VERSION ""

NS_ :

BS_:

BU_: XXX

BO_ 258 STEERING: 8 XXX
 SG_ STEER_ANGLE : 4|13@0+ (0.3187251,-1307.888) [-360|360] "deg" XXX
 SG_ STEERING_RATE : 20|13@0+ (1,-4096) [0|8191] "" XXX

BO_ 514 SPEED: 4 XXX
 SG_ SPEED_LEFT : 7|16@0+ (0.07,0) [0|65535] "m/s" XXX
 SG_ SPEED_RIGHT : 23|16@0+ (0.07,0) [0|1023] "m/s" XXX

BO_ 653 BRAKE_MODULE: 2 XXX
 SG_ BRAKE_PRESSURE : 15|8@0+ (1,0) [0|255] "" XXX
 SG_ BRAKE_PRESSED : 4|1@0+ (1,0) [0|4] "" XXX

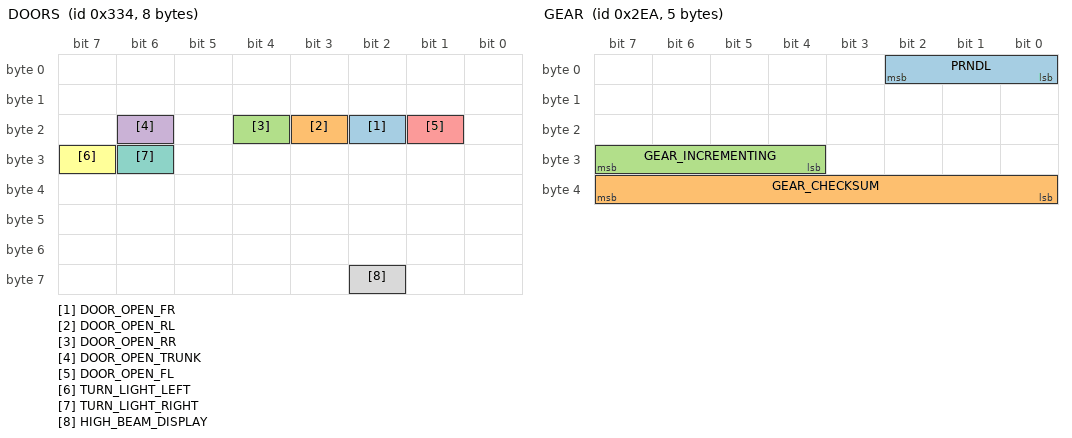
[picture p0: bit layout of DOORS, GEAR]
BO_ 820 DOORS: 8 XXX
 SG_ DOOR_OPEN_FR : 18|1@0+ (1,0) [0|1] "" XXX
 SG_ DOOR_OPEN_RL : 19|1@0+ (1,0) [0|1] "" XXX
 SG_ DOOR_OPEN_RR : 20|1@0+ (1,0) [0|1] "" XXX
 SG_ DOOR_OPEN_TRUNK : 22|1@0+ (1,0) [0|1] "" XXX
 SG_ DOOR_OPEN_FL : 17|1@0+ (1,0) [0|1] "" XXX
 SG_ TURN_LIGHT_LEFT : 31|1@0+ (1,0) [0|1] "" XXX
 SG_ TURN_LIGHT_RIGHT : 30|1@0+ (1,0) [0|1] "" XXX
 SG_ HIGH_BEAM_DISPLAY : 58|1@1+ (1,0) [0|1] "" XXX

BO_ 746 GEAR: 5 XXX
 SG_ PRNDL : 0|3@1+ (1,0) [0|7] "" XXX
 SG_ GEAR_CHECKSUM : 39|8@0+ (1,0) [0|255] "" XXX
 SG_ GEAR_INCREMENTING : 31|4@0+ (1,0) [0|15] "" XXX

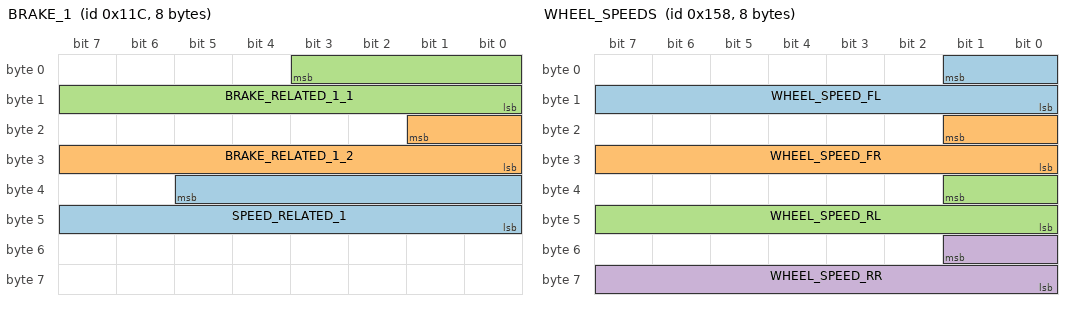
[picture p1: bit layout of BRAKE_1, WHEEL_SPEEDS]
BO_ 284 BRAKE_1: 8 XXX
 SG_ SPEED_RELATED_1 : 37|14@0+ (1,0) [0|255] "" XXX
 SG_ BRAKE_RELATED_1_2 : 17|10@0+ (1,0) [0|255] "" XXX
 SG_ BRAKE_RELATED_1_1 : 3|12@0+ (1,0) [0|255] "" XXX

BO_ 320 BRAKE_2: 8 XXX
 SG_ BRAKE_PRESSED : 2|3@0+ (1,0) [0|7] "" XXX
 SG_ SPEED_RELATED_2 : 47|8@0+ (1,0) [0|63] "" XXX

BO_ 736 TRIP: 8 XXX
 SG_ DISTANCE_COUNTER : 7|16@0+ (0,0) [0|65535] "Meters" XXX
 SG_ DISTANCE_COUNTER_2 : 23|16@0+ (1,0) [0|65535] "Meters" XXX

BO_ 344 WHEEL_SPEEDS: 8 XXX
 SG_ WHEEL_SPEED_FL : 1|10@0+ (1,0) [0|65535] "" XXX
 SG_ WHEEL_SPEED_FR : 17|10@0+ (1,0) [0|255] "" XXX
 SG_ WHEEL_SPEED_RL : 33|10@0+ (1,0) [0|3] "" XXX
 SG_ WHEEL_SPEED_RR : 49|10@0+ (1,0) [0|255] "" XXX

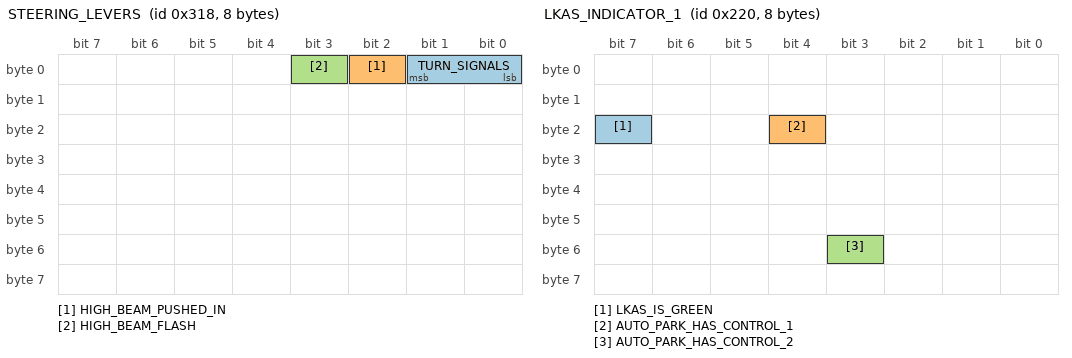
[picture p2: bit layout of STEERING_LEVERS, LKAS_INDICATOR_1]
BO_ 792 STEERING_LEVERS: 8 XXX
 SG_ TURN_SIGNALS : 1|2@0+ (1,0) [0|3] "" XXX
 SG_ HIGH_BEAM_PUSHED_IN : 2|1@1+ (1,0) [0|3] "" XXX
 SG_ HIGH_BEAM_FLASH : 3|1@1+ (1,0) [0|3] "" XXX

BO_ 264 ACCEL_PEDAL_MSG: 8 XXX
 SG_ ACCEL_PEDAL : 32|4@1+ (1,-7) [0|15] "" XXX

BO_ 464 SEATBELT_STATUS: 8 XXX
 SG_ SEATBELT_DRIVER_UNLATCHED : 13|1@0+ (1,0) [0|1] "" XXX

BO_ 544 LKAS_INDICATOR_1: 8 XXX
 SG_ LKAS_IS_GREEN : 23|1@0+ (1,0) [0|1] "" XXX
 SG_ AUTO_PARK_HAS_CONTROL_1 : 20|1@0+ (1,0) [0|1] "" XXX
 SG_ AUTO_PARK_HAS_CONTROL_2 : 51|1@1+ (1,0) [0|1] "" XXX

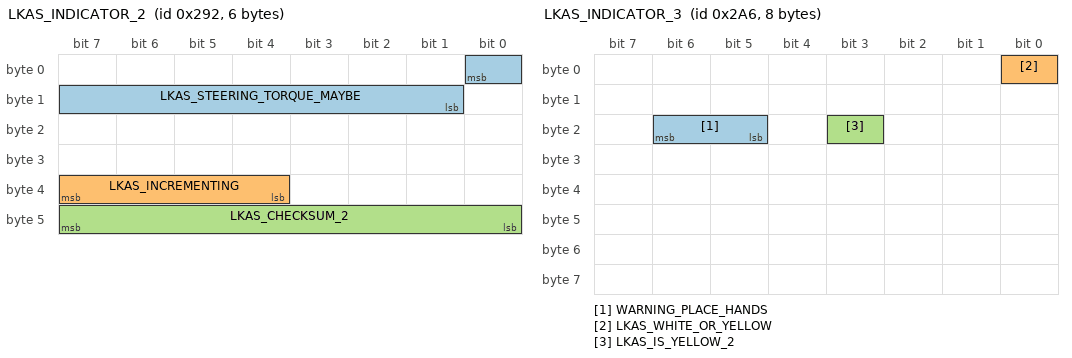
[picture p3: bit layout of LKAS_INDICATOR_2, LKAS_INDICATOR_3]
BO_ 658 LKAS_INDICATOR_2: 6 XXX
 SG_ LKAS_STEERING_TORQUE_MAYBE : 0|8@0- (1,0) [0|63] "" XXX
 SG_ LKAS_INCREMENTING : 39|4@0+ (1,0) [0|15] "" XXX
 SG_ LKAS_CHECKSUM_2 : 40|8@1+ (1,0) [0|255] "" XXX

BO_ 678 LKAS_INDICATOR_3: 8 XXX
 SG_ WARNING_PLACE_HANDS : 22|2@0+ (1,0) [0|3] "" XXX
 SG_ LKAS_WHITE_OR_YELLOW : 0|1@1+ (1,0) [0|1] "" XXX
 SG_ LKAS_IS_YELLOW_2 : 19|1@1+ (1,0) [0|1] "" XXX

BO_ 705 AUTO_PARK_BUTTON: 8 XXX
 SG_ AUTO_PARK_TOGGLE_2 : 8|1@1+ (1,0) [0|1] "" XXX
 SG_ AUTO_PARK_TOGGLE_1 : 11|1@0+ (1,0) [0|1] "" XXX

BO_ 719 AUTO_PARK_SIGNALS_1: 8 XXX
 SG_ AUTO_PARK_UNKNOWN_1 : 7|16@0+ (1,0) [0|31] "" XXX

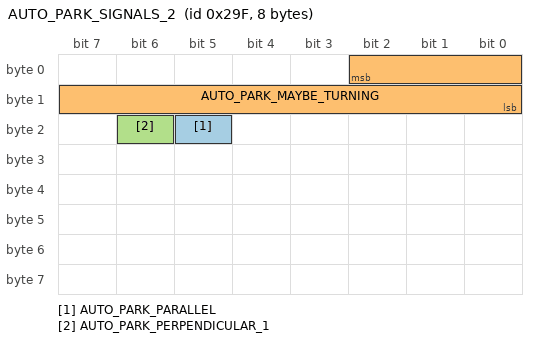
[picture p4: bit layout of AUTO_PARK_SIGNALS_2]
BO_ 671 AUTO_PARK_SIGNALS_2: 8 XXX
 SG_ AUTO_PARK_PARALLEL : 21|1@0+ (1,0) [0|1] "" XXX
 SG_ AUTO_PARK_MAYBE_TURNING : 2|11@0+ (1,0) [0|1023] "" XXX
 SG_ AUTO_PARK_PERPENDICULAR_1 : 22|1@0+ (1,0) [0|1] "" XXX

BO_ 784 AUTO_PARK_LESS_INTERESTING: 8 XXX
 SG_ AUTO_PARK_PERPENDICULAR_2 : 61|1@0+ (1,0) [0|255] "" XXX

BO_ 826 AUTO_PARK_SIGNALS_3: 8 XXX
 SG_ AUTO_PARK_HAS_CONTROL_3 : 1|1@0+ (1,0) [0|1] "" XXX
 SG_ HUMAN_HAS_CONTROL : 2|1@0+ (1,0) [0|1] "" XXX

BO_ 332 STEERING_2: 8 XXX
 SG_ STEER_ANGLE_2 : 7|13@0+ (0.3187251,-1307.888) [-360|360] "deg" XXX

BO_ 720 BLIND_SPOT_WARNINGS: 6 XXX
 SG_ BLIND_SPOT_RIGHT : 5|1@0+ (1,0) [0|1] "" XXX

BO_ 331 BRAKE_3: 8 XXX
 SG_ BRAKE_RELATED_3 : 7|16@0+ (1,0) [0|65535] "" XXX

BO_ 608 PARKSENSE_SIGNAL: 8 XXX
 SG_ PARKSENSE_DISABLED : 34|1@0+ (1,0) [0|1] "" XXX

BO_ 729 LKAS_STATUS_1: 5 XXX
 SG_ LKAS_STATUS_OK : 31|16@0+ (1,0) [0|65535] "" XXX

BO_ 274 NEW_MSG_112: 2 XXX

BO_ 290 NEW_MSG_122: 6 XXX

BO_ 376 NEW_MSG_178: 3 XXX

BO_ 288 NEW_MSG_120: 7 XXX
 SG_ UNKNOWN_INCREMENTING_120 : 47|4@0+ (1,0) [0|15] "" XXX
 SG_ UNKNOWN_CHECKSUM_120 : 55|8@0+ (1,0) [0|255] "" XXX

BO_ 257 NEW_MSG_101: 5 XXX

BO_ 388 NEW_MSG_184: 4 XXX

BO_ 448 NEW_MSG_1c0: 6 XXX

BO_ 456 NEW_MSG_1c8: 4 XXX

BO_ 560 NEW_MSG_230: 4 XXX

BO_ 564 NEW_MSG_234: 4 XXX

BO_ 571 NEW_MSG_23b: 3 XXX
 SG_ INCREMENTING_23B : 15|4@0+ (1,0) [0|15] "" XXX
 SG_ CHECKSUM_23B : 23|8@0+ (1,0) [0|255] "" XXX

BO_ 669 NEW_MSG_29d: 3 XXX
 SG_ INCREMENTING_29D : 15|4@0+ (1,0) [0|15] "" XXX
 SG_ CHECKSUM_29D : 16|8@1+ (1,0) [0|255] "" XXX

BO_ 825 NEW_MSG_339: 2 XXX

BO_ 856 NEW_MSG_358: 4 XXX

BO_ 860 NEW_MSG_35c: 6 XXX

BO_ 924 NEW_MSG_39c: 3 XXX

BO_ 969 NEW_MSG_3c9: 4 XXX

BO_ 974 NEW_MSG_3ce: 5 XXX

BO_ 993 NEW_MSG_3e1: 7 XXX

BO_ 838 NEW_MSG_346: 2 XXX

BO_ 926 NEW_MSG_39e: 3 XXX

CM_ SG_ 258 STEER_ANGLE "positive is left (counter-clockwise)";
CM_ SG_ 514 SPEED_LEFT "TODO find upper limit";
CM_ SG_ 653 BRAKE_PRESSURE "max seems to be 148";
CM_ SG_ 820 TURN_LIGHT_LEFT "oscillates with the light blinking";
CM_ SG_ 820 TURN_LIGHT_RIGHT "hazard blinks both right and left lights";
CM_ SG_ 746 PRNDL "4=D, 3=N, 2=R, 1=P";
CM_ SG_ 746 GEAR_CHECKSUM "different than the LKAS checksum. unknown non-simple algorithm. just build a lookup table for it.";
CM_ SG_ 284 SPEED_RELATED_1 "Another Speed Signal, Maybe RPMs?";
CM_ SG_ 284 BRAKE_RELATED_1_1 "Correlates with braking";
CM_ SG_ 320 BRAKE_PRESSED "Value is 5 when brake is pressed";
CM_ SG_ 792 TURN_SIGNALS "1=Left, 2=Right";
CM_ SG_ 792 HIGH_BEAM_FLASH "use this for genericToggle";
CM_ SG_ 264 ACCEL_PEDAL "not in ACC so seems to be actual pedal. Use for gasPressed";
CM_ SG_ 544 AUTO_PARK_HAS_CONTROL_1 "set when autopark has control";
CM_ SG_ 658 LKAS_INCREMENTING "each message increments, 0..f";
CM_ SG_ 658 LKAS_CHECKSUM_2 "checksum calculated with https://gist.github.com/adhintz/94bf8d19b9075539f50172ab0fb24ba1";
CM_ SG_ 678 WARNING_PLACE_HANDS "set when warning displays place hands on steering wheel";
CM_ SG_ 678 LKAS_WHITE_OR_YELLOW "set when indicator is yellow or white. could indicate lkas not on track.";
CM_ SG_ 678 LKAS_IS_YELLOW_2 "set when indicator is yellow. could indicate lkas is steering.";
CM_ SG_ 705 AUTO_PARK_TOGGLE_1 "set briefly when turning on or off self-parking";
CM_ SG_ 671 AUTO_PARK_PARALLEL "parallel parking mode";
CM_ SG_ 671 AUTO_PARK_MAYBE_TURNING "something with autopark turning the steering wheel maybe.";
CM_ SG_ 671 AUTO_PARK_PERPENDICULAR_1 "perpendicular parking mode";
CM_ SG_ 332 STEER_ANGLE_2 "slightly lags the other steer_angle signal. also more noisy.";
CM_ SG_ 720 BLIND_SPOT_RIGHT "yellow triangle alert on side view mirror when a car is in your blind spot";
CM_ SG_ 608 PARKSENSE_DISABLED "set if parksense is disabled";
CM_ SG_ 729 LKAS_STATUS_OK "Set to 0x0820 when LKAS system is plugged in.";
CM_ SG_ 288 UNKNOWN_CHECKSUM_120 "not the LKAS checksum";
VAL_ 746 PRNDL 4 "Drive" 3 "Neutral" 2 "Reverse" 1 "Park" ;
VAL_ 792 TURN_SIGNALS 2 "Right" 1 "Left" ;
